# PIC32MZ2025DAH169 register map
Vendor: Microchip
Registers are 32-bit, read-write, reset 0x0 unless marked. A register's access mark holds for its fields unless they carry their own. Addresses are absolute, and some are shared; only a register's first bit layout is shown; [hi:lo] are bit positions; {n}, {i} and the like mark numbered series.

## USB
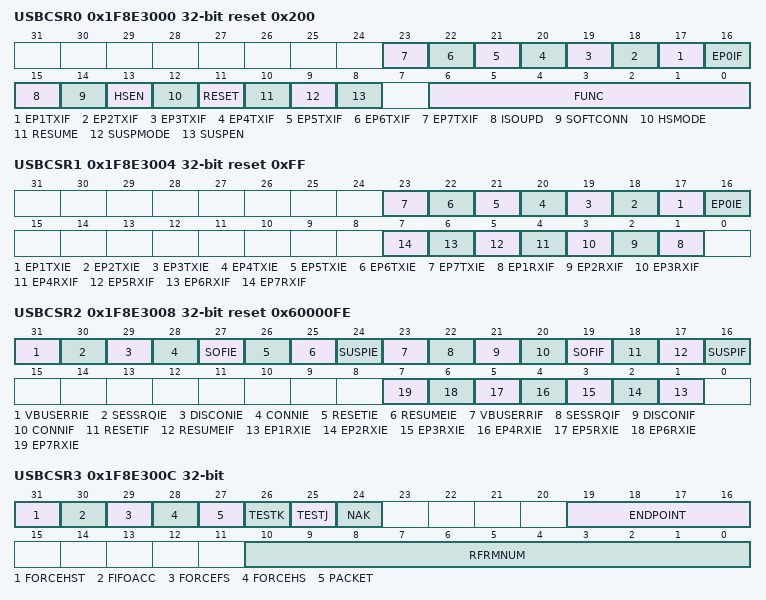
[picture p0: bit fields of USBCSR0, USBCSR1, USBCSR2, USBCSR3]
0x1F8E3000 USBCSR0 reset 0x200
  [n+16] EP{n}TXIF ro (n=1..7), [16] EP0IF ro, [15] ISOUPD, [14] SOFTCONN, [13] HSEN, [12] HSMODE ro, [11] RESET, [10] RESUME, [9] SUSPMODE, [8] SUSPEN, [6:0] FUNC
0x1F8E3004 USBCSR1 reset 0xFF
  [n+16] EP{n}TXIE ro (n=1..7), [16] EP0IE, [n] EP{n}RXIF (n=1..7)
0x1F8E3008 USBCSR2 reset 0x60000FE
  [31] VBUSERRIE, [30] SESSRQIE, [29] DISCONIE, [28] CONNIE, [27] SOFIE, [26] RESETIE, [25] RESUMEIE, [24] SUSPIE, [23] VBUSERRIF ro, [22] SESSRQIF ro, [21] DISCONIF ro, [20] CONNIF ro, [19] SOFIF ro, [18] RESETIF ro, [17] RESUMEIF ro, [16] SUSPIF ro, [n] EP{n}RXIE (n=1..7)
0x1F8E300C USBCSR3
  [31] FORCEHST, [30] FIFOACC, [29] FORCEFS, [28] FORCEHS, [27] PACKET, [26] TESTK, [25] TESTJ, [24] NAK, [19:16] ENDPOINT, [10:0] RFRMNUM
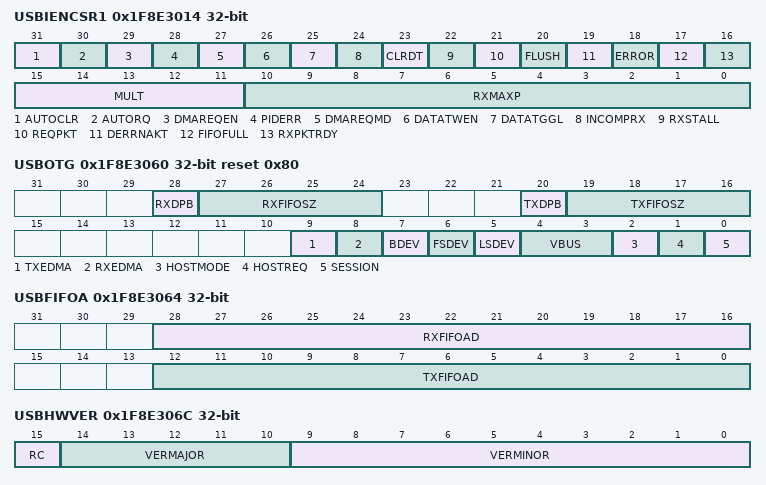
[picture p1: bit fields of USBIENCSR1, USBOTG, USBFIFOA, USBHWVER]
0x1F8E3014 USBIENCSR1
  [31] AUTOCLR, [30] AUTORQ, [29] DMAREQEN, [28] PIDERR, [27] DMAREQMD, [26] DATATWEN, [25] DATATGGL ro, [24] INCOMPRX, [23] CLRDT, [22] RXSTALL, [21] REQPKT, [20] FLUSH, [19] DERRNAKT ro, [18] ERROR, [17] FIFOFULL ro, [16] RXPKTRDY, [15:11] MULT, [10:0] RXMAXP
{0x1F8E3020+4i} USBFIFO{i} (i=0..7)
  [31:0] DATA
0x1F8E3060 USBOTG reset 0x80
  [28] RXDPB, [27:24] RXFIFOSZ, [20] TXDPB, [19:16] TXFIFOSZ, [9] TXEDMA, [8] RXEDMA, [7] BDEV ro, [6] FSDEV ro, [5] LSDEV ro, [4:3] VBUS ro, [2] HOSTMODE ro, [1] HOSTREQ, [0] SESSION
0x1F8E3064 USBFIFOA
  [28:16] RXFIFOAD, [12:0] TXFIFOAD
0x1F8E306C USBHWVER ro reset not defined — (power-on value ----------------0xxxxxxxxxxxxxxx)
  [15] RC, [14:10] VERMAJOR, [9:0] VERMINOR
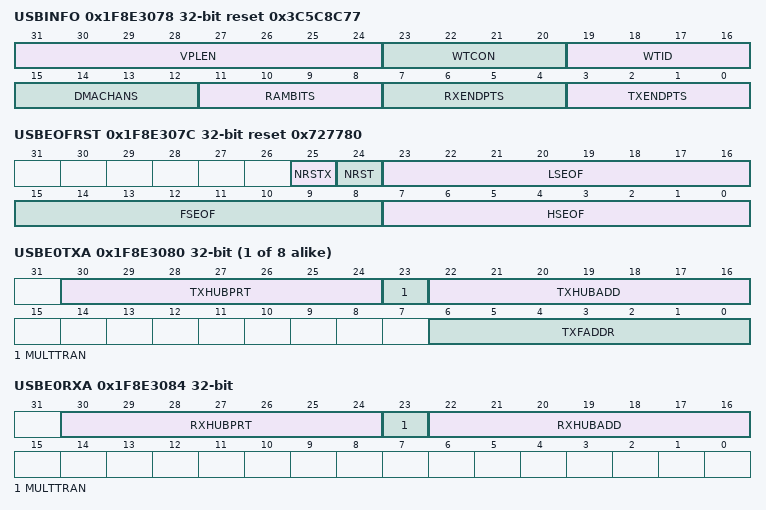
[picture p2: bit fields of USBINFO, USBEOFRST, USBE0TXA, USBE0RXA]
0x1F8E3078 USBINFO reset 0x3C5C8C77
  [31:24] VPLEN, [23:20] WTCON, [19:16] WTID, [15:12] DMACHANS ro, [11:8] RAMBITS ro, [7:4] RXENDPTS ro, [3:0] TXENDPTS ro
0x1F8E307C USBEOFRST reset 0x727780
  [25] NRSTX — Reset of XCLK Domain bit
  [24] NRST — Reset of CLK Domain bit
  [23:16] LSEOF
  [15:8] FSEOF
  [7:0] HSEOF
{0x1F8E3080+8i} USBE{i}TXA (i=0..7)
  [30:24] TXHUBPRT, [23] MULTTRAN, [22:16] TXHUBADD, [6:0] TXFADDR
0x1F8E3084 USBE0RXA
  [30:24] RXHUBPRT, [23] MULTTRAN, [22:16] RXHUBADD
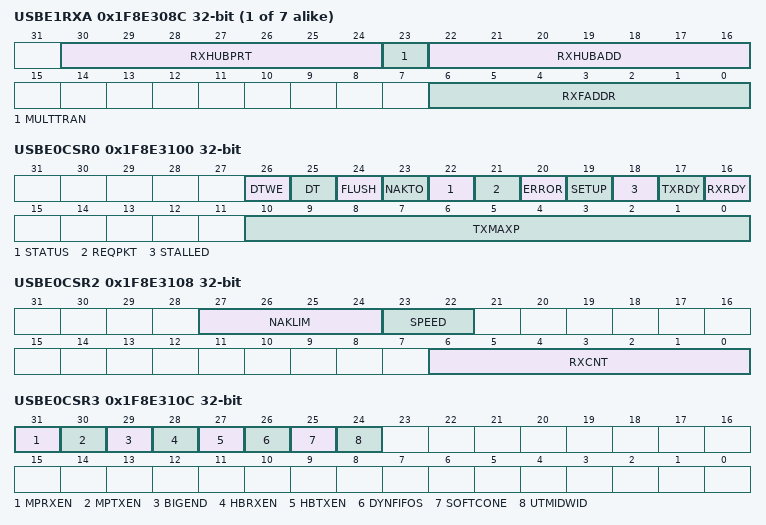
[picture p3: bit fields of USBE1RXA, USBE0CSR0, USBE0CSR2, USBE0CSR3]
{0x1F8E3084+8i} USBE{i}RXA (i=1..7)
  [30:24] RXHUBPRT, [23] MULTTRAN, [22:16] RXHUBADD, [6:0] RXFADDR
0x1F8E3100 USBE0CSR0
  [26] DTWE, [25] DT, [24] FLUSH, [23] NAKTO, [22] STATUS, [21] REQPKT, [20] ERROR, [19] SETUP, [18] STALLED, [17] TXRDY, [16] RXRDY, [10:0] TXMAXP
0x1F8E3108 USBE0CSR2
  [27:24] NAKLIM, [23:22] SPEED, [6:0] RXCNT
0x1F8E310C USBE0CSR3
  [31] MPRXEN, [30] MPTXEN, [29] BIGEND, [28] HBRXEN, [27] HBTXEN, [26] DYNFIFOS, [25] SOFTCONE, [24] UTMIDWID
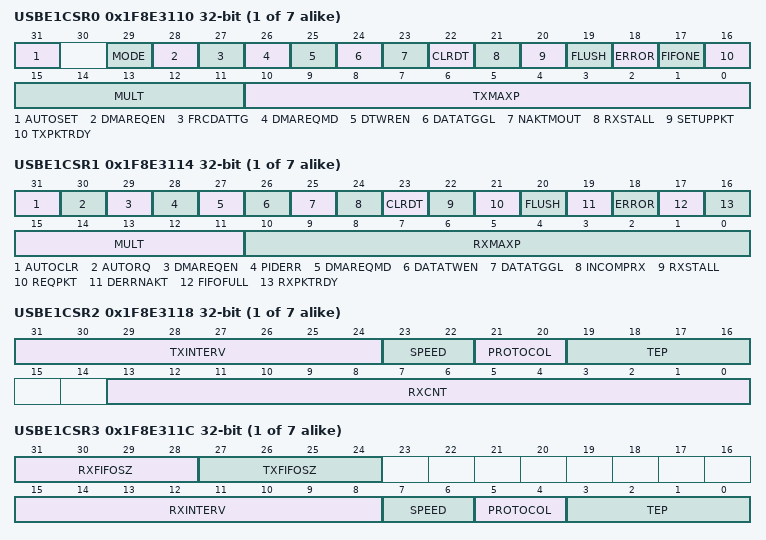
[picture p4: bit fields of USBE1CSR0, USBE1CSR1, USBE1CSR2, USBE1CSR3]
{0x1F8E3100+0x10*i} USBE{i}CSR0 (i=1..7)
  [31] AUTOSET, [29] MODE, [28] DMAREQEN, [27] FRCDATTG, [26] DMAREQMD, [25] DTWREN, [24] DATATGGL, [23] NAKTMOUT, [22] CLRDT, [21] RXSTALL, [20] SETUPPKT, [19] FLUSH, [18] ERROR, [17] FIFONE, [16] TXPKTRDY, [15:11] MULT, [10:0] TXMAXP
{0x1F8E3104+0x10*i} USBE{i}CSR1 (i=1..7)
  [31] AUTOCLR, [30] AUTORQ, [29] DMAREQEN, [28] PIDERR, [27] DMAREQMD, [26] DATATWEN, [25] DATATGGL, [24] INCOMPRX, [23] CLRDT, [22] RXSTALL, [21] REQPKT, [20] FLUSH, [19] DERRNAKT, [18] ERROR, [17] FIFOFULL, [16] RXPKTRDY, [15:11] MULT, [10:0] RXMAXP
{0x1F8E3108+0x10*i} USBE{i}CSR2 (i=1..7)
  [31:24] TXINTERV, [23:22] SPEED, [21:20] PROTOCOL, [19:16] TEP, [13:0] RXCNT
{0x1F8E310C+0x10*i} USBE{i}CSR3 (i=1..7)
  [31:28] RXFIFOSZ, [27:24] TXFIFOSZ, [15:8] RXINTERV, [7:6] SPEED, [5:4] PROTOCOL, [3:0] TEP
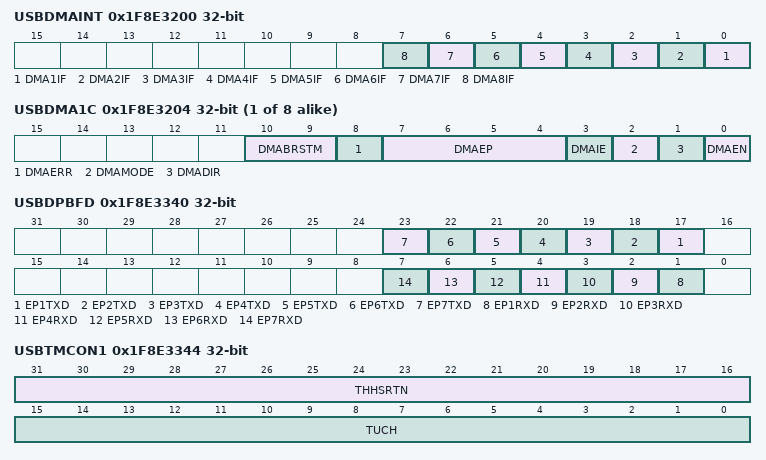
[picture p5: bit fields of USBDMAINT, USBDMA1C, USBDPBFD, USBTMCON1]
0x1F8E3200 USBDMAINT
  [n-1] DMA{n}IF (n=1..8)
{0x1F8E31F4+0x10*i} USBDMA{i}C (i=1..8)
  [10:9] DMABRSTM, [8] DMAERR, [7:4] DMAEP, [3] DMAIE, [2] DMAMODE, [1] DMADIR, [0] DMAEN
{0x1F8E31F8+0x10*i} USBDMA{i}A (i=1..8)
  [31:0] DMAADDR
{0x1F8E31FC+0x10*i} USBDMA{i}N (i=1..8)
  [31:0] DMACOUNT
{0x1F8E3300+4i} USBE{i}RPC (i=1..7)
  [15:0] RQPKTCNT
0x1F8E3340 USBDPBFD
  [n+16] EP{n}TXD (n=1..7), [n] EP{n}RXD (n=1..7)
0x1F8E3344 USBTMCON1 reset not defined — (power-on value xxxxxxxxxxxxxxxxxxxxxxxxxxxxxxxx)
  [31:16] THHSRTN, [15:0] TUCH
0x1F8E3348 USBTMCON2
  [3:0] THSBT
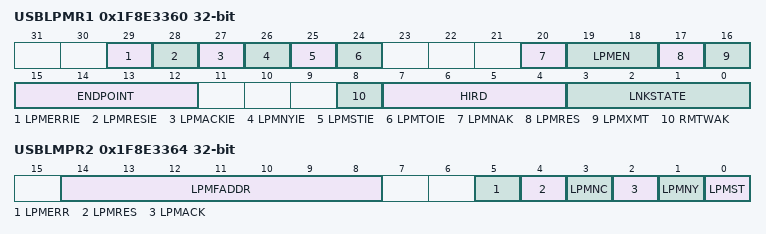
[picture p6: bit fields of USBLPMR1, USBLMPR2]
0x1F8E3360 USBLPMR1
  [29] LPMERRIE, [28] LPMRESIE, [27] LPMACKIE, [26] LPMNYIE, [25] LPMSTIE, [24] LPMTOIE, [20] LPMNAK, [19:18] LPMEN, [17] LPMRES, [16] LPMXMT, [15:12] ENDPOINT, [8] RMTWAK, [7:4] HIRD, [3:0] LNKSTATE
0x1F8E3364 USBLMPR2
  [14:8] LPMFADDR, [5] LPMERR, [4] LPMRES, [3] LPMNC, [2] LPMACK, [1] LPMNY, [0] LPMST
